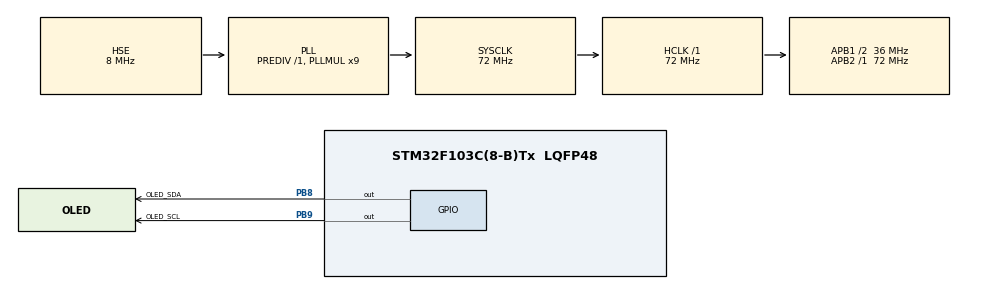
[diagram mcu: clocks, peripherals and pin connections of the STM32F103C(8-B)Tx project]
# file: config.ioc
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Mcu.Family=STM32F1
Mcu.Name=STM32F103C(8-B)Tx
Mcu.Package=LQFP48
NVIC.PriorityGroup=NVIC_PRIORITYGROUP_4
PA0-WKUP.Mode=SYS_WakeUp0
PA0-WKUP.Signal=SYS_WKUP
PA13.Mode=Serial_Wire
PA13.Signal=SYS_JTMS-SWDIO
PA14.Mode=Serial_Wire
PA14.Signal=SYS_JTCK-SWCLK
PB8.GPIO_Label=OLED_SDA
PB8.GPIO_ModeDefaultOutputPP=GPIO_MODE_OUTPUT_OD
PB8.GPIO_PuPd=GPIO_NOPULL
PB8.GPIO_Speed=GPIO_SPEED_FREQ_HIGH
PB8.PinState=GPIO_PIN_SET
PB8.Signal=GPIO_Output
PB9.GPIO_Label=OLED_SCL
PB9.GPIO_ModeDefaultOutputPP=GPIO_MODE_OUTPUT_OD
PB9.GPIO_PuPd=GPIO_NOPULL
PB9.GPIO_Speed=GPIO_SPEED_FREQ_HIGH
PB9.PinState=GPIO_PIN_SET
PB9.Signal=GPIO_Output
PC14-OSC32_IN.Mode=LSE-External-Oscillator
PC14-OSC32_IN.Signal=RCC_OSC32_IN
PC15-OSC32_OUT.Mode=LSE-External-Oscillator
PC15-OSC32_OUT.Signal=RCC_OSC32_OUT
PD0-OSC_IN.Mode=HSE-External-Oscillator
PD0-OSC_IN.Signal=RCC_OSC_IN
PD1-OSC_OUT.Mode=HSE-External-Oscillator
PD1-OSC_OUT.Signal=RCC_OSC_OUT
ProjectManager.HeapSize=0x200
ProjectManager.StackSize=0x400
ProjectManager.TargetToolchain=CMake
RCC.AHBFreq_Value=72000000
RCC.APB1CLKDivider=RCC_HCLK_DIV2
RCC.APB1Freq_Value=36000000
RCC.APB1TimFreq_Value=72000000
RCC.APB2Freq_Value=72000000
RCC.APB2TimFreq_Value=72000000
RCC.HCLKFreq_Value=72000000
RCC.PLLMUL=RCC_PLL_MUL9
RCC.PLLSourceVirtual=RCC_PLLSOURCE_HSE
RCC.RTCClockSelection=RCC_RTCCLKSOURCE_LSE
RCC.SYSCLKFreq_VALUE=72000000
RCC.SYSCLKSource=RCC_SYSCLKSOURCE_PLLCLK
RCC.USBFreq_Value=72000000
RTC.Date=1
RTC.Format=RTC_FORMAT_BCD
RTC.Hours=16
RTC.Minutes=20
RTC.Month=RTC_MONTH_JANUARY
RTC.OutPut=RTC_OUTPUTSOURCE_NONE
RTC.Seconds=0
RTC.WeekDay=RTC_WEEKDAY_MONDAY
RTC.Year=0
VP_RTC_No_RTC_Output.Mode=RTC_OUT_NO
VP_RTC_VS_RTC_Activate.Mode=RTC_Enabled
board=custom

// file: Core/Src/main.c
/* USER CODE BEGIN Header */
/**
  ******************************************************************************
  * @file           : main.c
  * @brief          : Main program body
  ******************************************************************************
  * @attention
  *
  * Copyright (c) 2026 STMicroelectronics.
  * All rights reserved.
  *
  * This software is licensed under terms that can be found in the LICENSE file
  * in the root directory of this software component.
  * If no LICENSE file comes with this software, it is provided AS-IS.
  *
  ******************************************************************************
  */
/* USER CODE END Header */
#include "main.h"
#include "rtc.h"
#include "gpio.h"

/* USER CODE BEGIN Includes */
#include "OLED.h"
#include "stm32f103xb.h"
#include "stm32f1xx_hal.h"
#include "stm32f1xx_hal_gpio.h"
#include "stm32f1xx_hal_pwr.h"
#include "stm32f1xx_hal_rtc.h"
#include "stm32f1xx_hal_rtc_ex.h"
#include <stdint.h>
/* USER CODE END Includes */

/* USER CODE BEGIN PV */
RTC_TimeTypeDef time;
RTC_DateTypeDef date;
RTC_AlarmTypeDef alarm;

/* USER CODE END PV */

void SystemClock_Config(void);

int main(void)
{

  /* MCU Configuration--------------------------------------------------------*/

  /* Reset of all peripherals, Initializes the Flash interface and the Systick. */
  HAL_Init();

  /* Configure the system clock */
  SystemClock_Config();

  /* Initialize all configured peripherals */
  MX_GPIO_Init();
  MX_RTC_Init();
  /* USER CODE BEGIN 2 */
  OLED_Init();
  OLED_ShowString(1, 7, "RTC");
  OLED_ShowString(2, 1, "Time: HH:MM:SS");
  OLED_ShowString(4, 1, "MCU Running");

  HAL_RTC_GetTime(&hrtc, &time, RTC_FORMAT_BCD);
  OLED_ShowHexNum(2, 7, time.Hours, 2);
  OLED_ShowHexNum(2, 10, time.Minutes, 2);
  OLED_ShowHexNum(2, 13, time.Seconds, 2);

  // 设定闹钟在当前时刻加5秒
  alarm.Alarm = RTC_ALARM_A;
  alarm.AlarmTime.Hours = time.Hours;
  alarm.AlarmTime.Minutes = time.Minutes;
  alarm.AlarmTime.Seconds = time.Seconds + 5;
  HAL_RTC_SetAlarm_IT(&hrtc, &alarm, RTC_FORMAT_BCD);

  HAL_Delay(500);
  OLED_ShowString(4, 1, "           ");
  // 进入Standby模式前，需手动清除WakeUp标志位、使能WakeUpPin、使能StandBy Debug（方便调试）
  __HAL_PWR_CLEAR_FLAG(PWR_FLAG_WU);
  HAL_PWR_EnableWakeUpPin(PWR_WAKEUP_PIN1);
  HAL_DBGMCU_EnableDBGStandbyMode();
  HAL_PWR_EnterSTANDBYMode();
  /* USER CODE END 2 */

  /* Infinite loop */
  while (1)
  {
  }
}

void SystemClock_Config(void)
{
  RCC_OscInitTypeDef RCC_OscInitStruct = {0};
  RCC_ClkInitTypeDef RCC_ClkInitStruct = {0};
  RCC_PeriphCLKInitTypeDef PeriphClkInit = {0};

  /** Initializes the RCC Oscillators according to the specified parameters
  * in the RCC_OscInitTypeDef structure.
  */
  RCC_OscInitStruct.OscillatorType = RCC_OSCILLATORTYPE_HSE|RCC_OSCILLATORTYPE_LSE;
  RCC_OscInitStruct.HSEState = RCC_HSE_ON;
  RCC_OscInitStruct.HSEPredivValue = RCC_HSE_PREDIV_DIV1;
  RCC_OscInitStruct.LSEState = RCC_LSE_ON;
  RCC_OscInitStruct.HSIState = RCC_HSI_ON;
  RCC_OscInitStruct.PLL.PLLState = RCC_PLL_ON;
  RCC_OscInitStruct.PLL.PLLSource = RCC_PLLSOURCE_HSE;
  RCC_OscInitStruct.PLL.PLLMUL = RCC_PLL_MUL9;
  if (HAL_RCC_OscConfig(&RCC_OscInitStruct) != HAL_OK)
  {
    Error_Handler();
  }

  /** Initializes the CPU, AHB and APB buses clocks
  */
  RCC_ClkInitStruct.ClockType = RCC_CLOCKTYPE_HCLK|RCC_CLOCKTYPE_SYSCLK
                              |RCC_CLOCKTYPE_PCLK1|RCC_CLOCKTYPE_PCLK2;
  RCC_ClkInitStruct.SYSCLKSource = RCC_SYSCLKSOURCE_PLLCLK;
  RCC_ClkInitStruct.AHBCLKDivider = RCC_SYSCLK_DIV1;
  RCC_ClkInitStruct.APB1CLKDivider = RCC_HCLK_DIV2;
  RCC_ClkInitStruct.APB2CLKDivider = RCC_HCLK_DIV1;

  if (HAL_RCC_ClockConfig(&RCC_ClkInitStruct, FLASH_LATENCY_2) != HAL_OK)
  {
    Error_Handler();
  }
  PeriphClkInit.PeriphClockSelection = RCC_PERIPHCLK_RTC;
  PeriphClkInit.RTCClockSelection = RCC_RTCCLKSOURCE_LSE;
  if (HAL_RCCEx_PeriphCLKConfig(&PeriphClkInit) != HAL_OK)
  {
    Error_Handler();
  }
}

void Error_Handler(void)
{
  __disable_irq();
  while (1)
  {
  }
}
